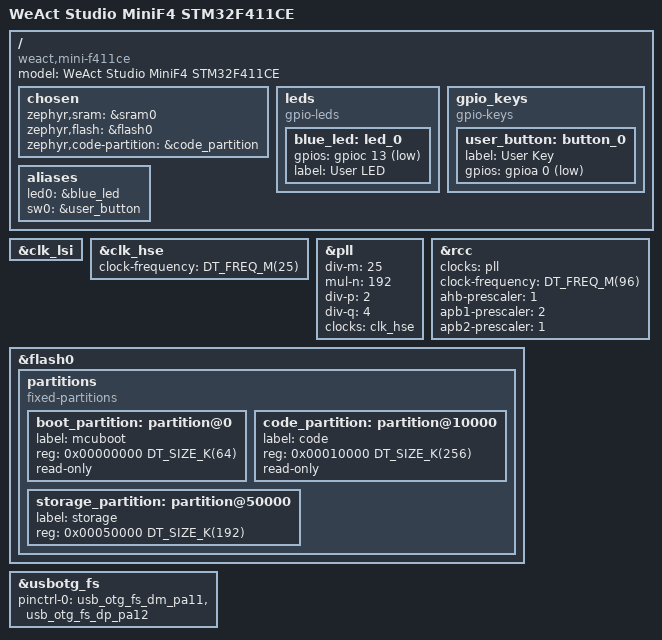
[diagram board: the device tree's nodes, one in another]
/*
 * Copyright (c) 2022 The ZMK Contributors
 * SPDX-License-Identifier: MIT
 */

/dts-v1/;
#include <st/f4/stm32f411Xe.dtsi>
#include <st/f4/stm32f411c(c-e)ux-pinctrl.dtsi>
#include <dt-bindings/zmk/matrix_transform.h>

/ {
	model = "WeAct Studio MiniF4 STM32F411CE";
	compatible = "weact,mini-f411ce";

	chosen {
		zephyr,sram = &sram0;
		zephyr,flash = &flash0;
		zephyr,code-partition = &code_partition;
	};

	leds {
		compatible = "gpio-leds";
		blue_led: led_0 {
			gpios = <&gpioc 13 GPIO_ACTIVE_LOW>;
			label = "User LED";
		};
	};

	gpio_keys {
		compatible = "gpio-keys";
		user_button: button_0 {
			label = "User Key";
			gpios = <&gpioa 0 (GPIO_ACTIVE_LOW | GPIO_PULL_UP)>;
		};
	};

	aliases {
		led0 = &blue_led;
		sw0 = &user_button;
	};
};

&clk_lsi {
	status = "okay";
};

&clk_hse {
	clock-frequency = <DT_FREQ_M(25)>;
	status = "okay";
};

&pll {
	div-m = <25>;
	mul-n = <192>;
	div-p = <2>;
	div-q = <4>;
	clocks = <&clk_hse>;
	status = "okay";
};

&rcc {
	clocks = <&pll>;
	clock-frequency = <DT_FREQ_M(96)>;
	ahb-prescaler = <1>;
	apb1-prescaler = <2>;
	apb2-prescaler = <1>;
};

&flash0 {
	partitions {
		compatible = "fixed-partitions";
		#address-cells = <1>;
		#size-cells = <1>;

		boot_partition: partition@0 {
			label = "mcuboot";
			reg = <0x00000000 DT_SIZE_K(64)>;
			read-only;
		};

		code_partition: partition@10000 {
			label = "code";
			reg = <0x00010000 DT_SIZE_K(256)>;
			read-only;
		};

		/*
		 * Storage partition will be used by FCB/LittleFS/NVS
		 * if enabled.
		 */
		storage_partition: partition@50000 {
			label = "storage";
			reg = <0x00050000 DT_SIZE_K(192)>;
		};
	};
};

&usbotg_fs {
	pinctrl-0 = <&usb_otg_fs_dm_pa11 &usb_otg_fs_dp_pa12>;
	pinctrl-names = "default";
	status = "okay";
};

zephyr_udc0: &usbotg_fs {};
